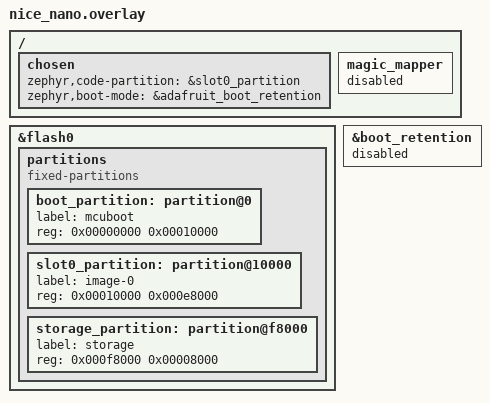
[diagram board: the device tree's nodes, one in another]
&flash0 {
	/delete-node/ partitions;

	partitions {
		compatible = "fixed-partitions";
		#address-cells = <1>;
		#size-cells = <1>;

		boot_partition: partition@0 {
			label = "mcuboot";
			reg = <0x00000000 0x00010000>;
		};

		slot0_partition: partition@10000 {
			label = "image-0";
			reg = <0x00010000 0x000e8000>;
		};

		storage_partition: partition@f8000 {
			label = "storage";
			reg = <0x000f8000 0x00008000>;
		};
	};
};

/ {
	chosen {
		zephyr,code-partition = &slot0_partition;
		zephyr,boot-mode = &adafruit_boot_retention;
	};

	magic_mapper {
		status = "disabled";
	};
};

&boot_retention {
	status = "disabled";
};
